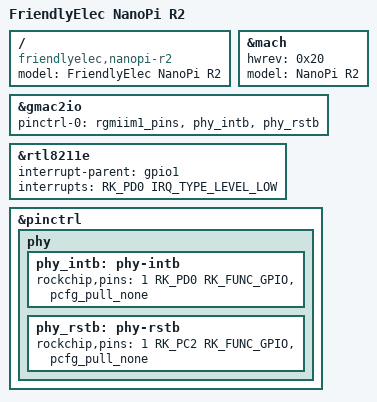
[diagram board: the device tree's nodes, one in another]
// SPDX-License-Identifier: (GPL-2.0+ OR MIT)
/*
 * Copyright (c) 2019 FriendlyElec Computer Tech. Co., Ltd.
 * (http://www.friendlyarm.com)
 */

/dts-v1/;
#include "rk3328-nanopi-r2s.dts"

/ {
	model = "FriendlyElec NanoPi R2";
	compatible = "friendlyelec,nanopi-r2", "rockchip,rk3328";
};

&mach {
	hwrev = <0x20>;
	model = "NanoPi R2";
};

&gmac2io {
	pinctrl-0 = <&rgmiim1_pins>, <&phy_intb>, <&phy_rstb>;
};

&rtl8211e {
	interrupt-parent = <&gpio1>;
	interrupts = <RK_PD0 IRQ_TYPE_LEVEL_LOW>;
};

&pinctrl {
	phy {
		phy_intb: phy-intb {
			rockchip,pins = <1 RK_PD0 RK_FUNC_GPIO &pcfg_pull_none>;
		};

		phy_rstb: phy-rstb {
			rockchip,pins = <1 RK_PC2 RK_FUNC_GPIO &pcfg_pull_none>;
		};
	};
};
